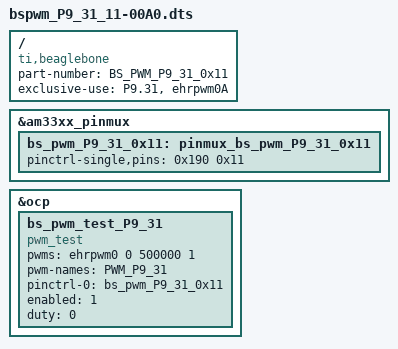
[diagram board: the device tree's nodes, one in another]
/*
 * Copyright (C) 2013 CircuitCo
 * Copyright (C) 2013 Texas Instruments
 *
 * This program is free software; you can redistribute it and/or modify
 * it under the terms of the GNU General Public License version 2 as
 * published by the Free Software Foundation.
 *
 * This is a template-generated file from BoneScript
 */
/dts-v1/;
/plugin/;

/ {
	compatible = "ti,beaglebone", "ti,beaglebone-black";

	/* identification */
	part-number = "BS_PWM_P9_31_0x11";

	/* state the resources this cape uses */
	exclusive-use =
		/* the pin header uses */
		"P9.31",
		/* the hardware IP uses */
		"ehrpwm0A";

	fragment@0 {
		target = <&am33xx_pinmux>;
		__overlay__ {
			bs_pwm_P9_31_0x11: pinmux_bs_pwm_P9_31_0x11 {
				pinctrl-single,pins = <0x190 0x11>;
			};
		};
	};

	fragment@1 {
		target = <&ocp>;
		__overlay__ {
			bs_pwm_test_P9_31 {
				compatible	= "pwm_test";
				pwms 		= <&ehrpwm0 0 500000 1>;
				pwm-names 	= "PWM_P9_31";

				pinctrl-names	= "default";
				pinctrl-0	= <&bs_pwm_P9_31_0x11>;

				enabled		= <1>;
				duty		= <0>;
				status 		= "okay";
			};
		};
	};
};
